VERSION ""

NS_ :

BS_:

BU_: MCU1 RPI5

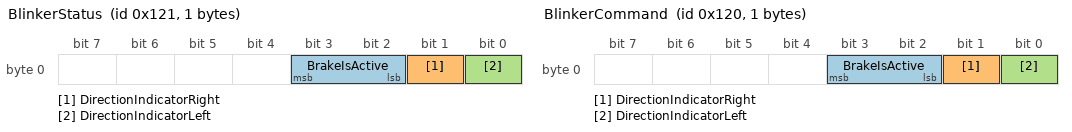
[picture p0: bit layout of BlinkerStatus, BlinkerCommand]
BO_ 289 BlinkerStatus: 1 Vector__XXX
 SG_ BrakeIsActive : 2|2@1+ (1,0) [0|3] "" Vector__XXX
 SG_ DirectionIndicatorRight : 1|1@1+ (1,0) [0|1] "" Vector__XXX
 SG_ DirectionIndicatorLeft : 0|1@1+ (1,0) [0|1] "" Vector__XXX

BO_ 288 BlinkerCommand: 1 RPI5
 SG_ BrakeIsActive : 2|2@1+ (1,0) [0|3] ""  MCU1
 SG_ DirectionIndicatorRight : 1|1@1+ (1,0) [0|1] ""  MCU1
 SG_ DirectionIndicatorLeft : 0|1@1+ (1,0) [0|1] ""  MCU1

CM_ SG_ 289 BrakeIsActive "Vehicle.Body.Lights.Brake.IsActive";
CM_ SG_ 289 DirectionIndicatorRight "Vehicle.Body.Lights.DirectionIndicator.Right.IsSignaling";
CM_ SG_ 289 DirectionIndicatorLeft "Vehicle.Body.Lights.DirectionIndicator.Left.IsSignaling";
CM_ SG_ 288 BrakeIsActive "Vehicle.Body.Lights.Brake.IsActive";
CM_ SG_ 288 DirectionIndicatorRight "Vehicle.Body.Lights.DirectionIndicator.Right.IsSignaling";
CM_ SG_ 288 DirectionIndicatorLeft "Vehicle.Body.Lights.DirectionIndicator.Left.IsSignaling";
BA_DEF_  "BusType" STRING ;
BA_DEF_DEF_  "BusType" "CAN";
